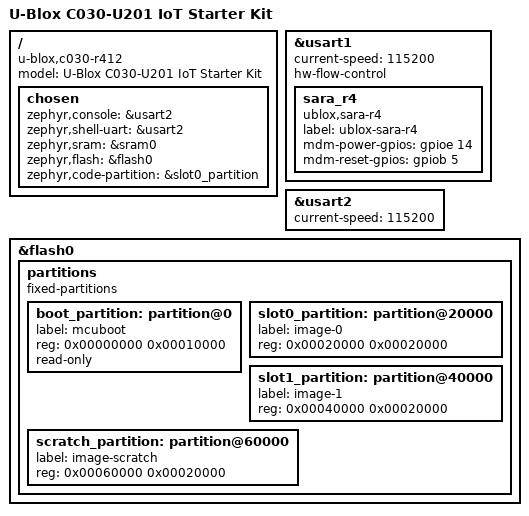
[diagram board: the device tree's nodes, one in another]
/*
 * Copyright (c) 2017 Linaro Limited
 *
 * SPDX-License-Identifier: Apache-2.0
 */

/dts-v1/;
#include <st/f4/stm32f437vX.dtsi>
/* #include "arduino_r3_connector.dtsi" */


/ {
	model = "U-Blox C030-U201 IoT Starter Kit";
	compatible = "u-blox,c030-r412";

	chosen {
		zephyr,console = &usart2;
		zephyr,shell-uart = &usart2;
		zephyr,sram = &sram0;
		zephyr,flash = &flash0;
		zephyr,code-partition = &slot0_partition;
	};
};

&usart1 {
	current-speed = <115200>;
	status = "okay";

	/* Enable hardware flow control for interfacing with SARA-R4 module. */
	hw-flow-control;

	/* SARA-R4 GPIO(s). 
	 * mdm-power-gpios = PE14 
	 * mdm-reset-gpios = PB5 */
	sara_r4 {
		compatible = "ublox,sara-r4";
		label = "ublox-sara-r4";
		status = "okay";

		mdm-power-gpios = <&gpioe 14 0>;
		mdm-reset-gpios = <&gpiob 5 0>;
		
		/* mdm-vint-gpios = <&gpio0 2 0>; */
	};
};

&usart2 {
	current-speed = <115200>;
	status = "okay";
};

&flash0 {
	/*
	 * For more information, see:
	 * http://docs.zephyrproject.org/latest/guides/dts/index.html#flash-partitions
	 */
	partitions {
		compatible = "fixed-partitions";
		#address-cells = <1>;
		#size-cells = <1>;

		boot_partition: partition@0 {
			label = "mcuboot";
			reg = <0x00000000 0x00010000>;
			read-only;
		};

		/*
		 * The flash starting at offset 0x10000 and ending at
		 * offset 0x1ffff is reserved for use by the application.
		 */

		slot0_partition: partition@20000 {
			label = "image-0";
			reg = <0x00020000 0x00020000>;
		};
		slot1_partition: partition@40000 {
			label = "image-1";
			reg = <0x00040000 0x00020000>;
		};
		scratch_partition: partition@60000 {
			label = "image-scratch";
			reg = <0x00060000 0x00020000>;
		};
	};

};
